AUTOSAR XML (schema 4-2-2)
package /Components
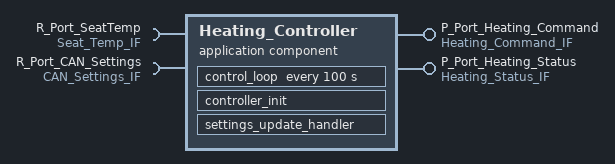
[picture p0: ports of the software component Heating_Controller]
  application sw component type Heating_Controller
    provide port P_Port_Heating_Command: provided-interface=Heating_Command_IF
    provide port P_Port_Heating_Status: provided-interface=Heating_Status_IF
    require port R_Port_SeatTemp: required-interface=Seat_Temp_IF
    require port R_Port_CAN_Settings: required-interface=CAN_Settings_IF
    behavior Heating_Controller_Internal
      data received event settings_update_event: start-on-event=settings_update_handler
      init event controller_init_event: start-on-event=controller_init
      timing event control_loop_event: start-on-event=control_loop, period=100
      runnable controller_init
        data-send-points:
          access VA_Init_Seat1_Command_Level: accessed-variable=P_Port_Heating_Command.Seat1_Command_Level.Seat1_Command_Level
          access VA_Init_Seat2_Command_Level: accessed-variable=P_Port_Heating_Command.Seat2_Command_Level.Seat2_Command_Level
      runnable control_loop: minimum-start-interval=100
        data-read-access:
          6 x access:
            VA_Read_Seat1_Temp_A: accessed-variable=R_Port_SeatTemp.Seat1_Temp_A.Seat1_Temp_A
            VA_Read_Seat1_Temp_B: accessed-variable=R_Port_SeatTemp.Seat1_Temp_B.Seat1_Temp_B
            VA_Read_Seat2_Temp_A: accessed-variable=R_Port_SeatTemp.Seat2_Temp_A.Seat2_Temp_A
            VA_Read_Seat2_Temp_B: accessed-variable=R_Port_SeatTemp.Seat2_Temp_B.Seat2_Temp_B
            VA_Read_Seat1_Target_Level: accessed-variable=R_Port_CAN_Settings.Seat1_Target_Level.Seat1_Target_Level
            VA_Read_Seat2_Target_Level: accessed-variable=R_Port_CAN_Settings.Seat2_Target_Level.Seat2_Target_Level
        data-send-points:
          6 x access:
            VA_Send_Seat1_Command_Level: accessed-variable=P_Port_Heating_Command.Seat1_Command_Level.Seat1_Command_Level
            VA_Send_Seat2_Command_Level: accessed-variable=P_Port_Heating_Command.Seat2_Command_Level.Seat2_Command_Level
            VA_Send_Seat1_Actual_Level: accessed-variable=P_Port_Heating_Status.Seat1_Actual_Level.Seat1_Actual_Level
            VA_Send_Seat2_Actual_Level: accessed-variable=P_Port_Heating_Status.Seat2_Actual_Level.Seat2_Actual_Level
            VA_Send_Seat1_Fault: accessed-variable=P_Port_Heating_Status.Seat1_Fault.Seat1_Fault
            VA_Send_Seat2_Fault: accessed-variable=P_Port_Heating_Status.Seat2_Fault.Seat2_Fault
        parameter access PA_Temp_Threshold: accessed-parameter=R_Port_SeatTemp.Seat1_Temp_A
        parameter access PA_Hysteresis: accessed-parameter=R_Port_CAN_Settings.Seat1_Target_Level
      runnable settings_update_handler: minimum-start-interval=50
        data-read-access:
          access VA_Event_Read_Seat1_Target_Level: accessed-variable=R_Port_CAN_Settings.Seat1_Target_Level.Seat1_Target_Level
          access VA_Event_Read_Seat2_Target_Level: accessed-variable=R_Port_CAN_Settings.Seat2_Target_Level.Seat2_Target_Level
